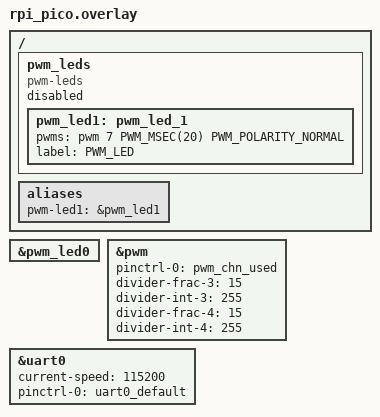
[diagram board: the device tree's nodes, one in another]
#include "rpi_pico-pinctrl.dtsi"

/ {
pwm_leds {
		compatible = "pwm-leds";
		status = "disabled";
		pwm_led1: pwm_led_1 {
			pwms = <&pwm 7 PWM_MSEC(20) PWM_POLARITY_NORMAL>;
			label = "PWM_LED";
		};
	};

	aliases {
		pwm-led1 = &pwm_led1;
	};
};


&pwm_led0 {
	status = "okay";
};

&pwm {
	status = "okay";

	pinctrl-0 = <&pwm_chn_used>;

	// for pwm chanel 3 A and B

	divider-frac-3 = <15>;
	divider-int-3 = <255>;
	
	// for pwm chanel 4 A and B
	
	divider-frac-4 = <15>;
	divider-int-4 = <255>;
};

&uart0 {
	current-speed = <115200>;
	status = "okay";
	pinctrl-0 = <&uart0_default>;
	pinctrl-names = "default";
};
